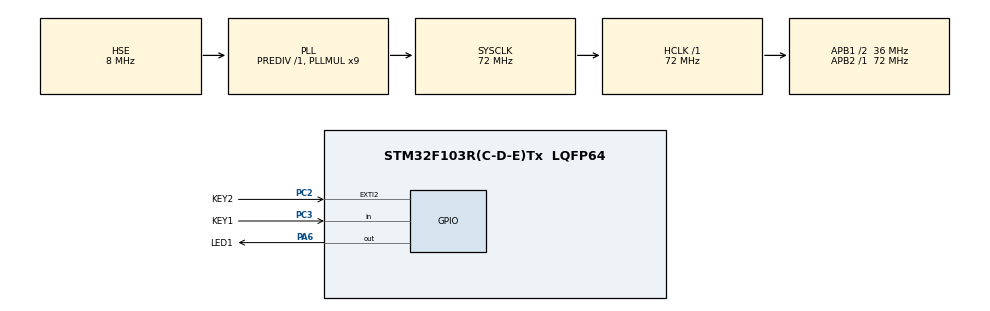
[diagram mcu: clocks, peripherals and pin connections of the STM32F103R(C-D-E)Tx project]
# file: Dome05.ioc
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Mcu.Family=STM32F1
Mcu.Name=STM32F103R(C-D-E)Tx
Mcu.Package=LQFP64
NVIC.EXTI2_IRQn=true\:2\:0\:true\:false\:true\:true\:true
NVIC.PriorityGroup=NVIC_PRIORITYGROUP_4
PA13.Mode=Serial_Wire
PA13.Signal=SYS_JTMS-SWDIO
PA14.Mode=Serial_Wire
PA14.Signal=SYS_JTCK-SWCLK
PA6.GPIO_Label=LED1
PA6.GPIO_PuPd=GPIO_PULLUP
PA6.PinState=GPIO_PIN_SET
PA6.Signal=GPIO_Output
PC2.GPIO_Label=KEY2
PC2.GPIO_ModeDefaultEXTI=GPIO_MODE_IT_RISING_FALLING
PC2.Signal=GPXTI2
PC3.GPIO_Label=KEY1
PC3.GPIO_PuPd=GPIO_NOPULL
PC3.Signal=GPIO_Input
PD0-OSC_IN.Mode=HSE-External-Oscillator
PD0-OSC_IN.Signal=RCC_OSC_IN
PD1-OSC_OUT.Mode=HSE-External-Oscillator
PD1-OSC_OUT.Signal=RCC_OSC_OUT
ProjectManager.HeapSize=0x200
ProjectManager.StackSize=0x400
ProjectManager.TargetToolchain=MDK-ARM V5.32
RCC.AHBFreq_Value=72000000
RCC.APB1CLKDivider=RCC_HCLK_DIV2
RCC.APB1Freq_Value=36000000
RCC.APB1TimFreq_Value=72000000
RCC.APB2Freq_Value=72000000
RCC.APB2TimFreq_Value=72000000
RCC.HCLKFreq_Value=72000000
RCC.PLLMUL=RCC_PLL_MUL9
RCC.PLLSourceVirtual=RCC_PLLSOURCE_HSE
RCC.SYSCLKFreq_VALUE=72000000
RCC.SYSCLKSource=RCC_SYSCLKSOURCE_PLLCLK
RCC.USBFreq_Value=72000000
board=custom

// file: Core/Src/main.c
/* USER CODE BEGIN Header */
/**
  ******************************************************************************
  * @file           : main.c
  * @brief          : Main program body
  ******************************************************************************
  * @attention
  *
  * Copyright (c) 2025 STMicroelectronics.
  * All rights reserved.
  *
  * This software is licensed under terms that can be found in the LICENSE file
  * in the root directory of this software component.
  * If no LICENSE file comes with this software, it is provided AS-IS.
  *
  ******************************************************************************
  */
/* USER CODE END Header */
#include "main.h"
#include "gpio.h"

void SystemClock_Config(void);

int main(void)
{

  /* MCU Configuration--------------------------------------------------------*/

  /* Reset of all peripherals, Initializes the Flash interface and the Systick. */
  HAL_Init();

  /* Configure the system clock */
  SystemClock_Config();

  /* Initialize all configured peripherals */
  MX_GPIO_Init();

  /* Infinite loop */
  /* USER CODE BEGIN WHILE */
  while (1)
  {
		HAL_Delay(5000);
		if(HAL_GPIO_ReadPin(KEY1_GPIO_Port, KEY1_Pin) == GPIO_PIN_RESET) {
			HAL_Delay(10);
			 if(HAL_GPIO_ReadPin(KEY1_GPIO_Port, KEY1_Pin) == GPIO_PIN_RESET) {
				 HAL_GPIO_TogglePin(LED1_GPIO_Port,LED1_Pin);
				 //HAL_Delay(3000);
				 while(HAL_GPIO_ReadPin(KEY1_GPIO_Port, KEY1_Pin) == GPIO_PIN_RESET);
			 }
		 }
    /* USER CODE END WHILE */

  }
}

void SystemClock_Config(void)
{
  RCC_OscInitTypeDef RCC_OscInitStruct = {0};
  RCC_ClkInitTypeDef RCC_ClkInitStruct = {0};

  /** Initializes the RCC Oscillators according to the specified parameters
  * in the RCC_OscInitTypeDef structure.
  */
  RCC_OscInitStruct.OscillatorType = RCC_OSCILLATORTYPE_HSE;
  RCC_OscInitStruct.HSEState = RCC_HSE_ON;
  RCC_OscInitStruct.HSEPredivValue = RCC_HSE_PREDIV_DIV1;
  RCC_OscInitStruct.HSIState = RCC_HSI_ON;
  RCC_OscInitStruct.PLL.PLLState = RCC_PLL_ON;
  RCC_OscInitStruct.PLL.PLLSource = RCC_PLLSOURCE_HSE;
  RCC_OscInitStruct.PLL.PLLMUL = RCC_PLL_MUL9;
  if (HAL_RCC_OscConfig(&RCC_OscInitStruct) != HAL_OK)
  {
    Error_Handler();
  }
  /** Initializes the CPU, AHB and APB buses clocks
  */
  RCC_ClkInitStruct.ClockType = RCC_CLOCKTYPE_HCLK|RCC_CLOCKTYPE_SYSCLK
                              |RCC_CLOCKTYPE_PCLK1|RCC_CLOCKTYPE_PCLK2;
  RCC_ClkInitStruct.SYSCLKSource = RCC_SYSCLKSOURCE_PLLCLK;
  RCC_ClkInitStruct.AHBCLKDivider = RCC_SYSCLK_DIV1;
  RCC_ClkInitStruct.APB1CLKDivider = RCC_HCLK_DIV2;
  RCC_ClkInitStruct.APB2CLKDivider = RCC_HCLK_DIV1;

  if (HAL_RCC_ClockConfig(&RCC_ClkInitStruct, FLASH_LATENCY_2) != HAL_OK)
  {
    Error_Handler();
  }
}

/* USER CODE BEGIN 4 */
uint32_t falling_tick = 0;
uint32_t rising_tick = 0;
 void HAL_GPIO_EXTI_Callback(uint16_t GPIO_Pin){
//	 if(GPIO_Pin == KEY2_Pin) {
//		HAL_Delay(10);
//		if(HAL_GPIO_ReadPin(KEY2_GPIO_Port,KEY2_Pin) == 0){
//			HAL_GPIO_TogglePin(LED1_GPIO_Port,LED1_Pin);
//		}
//
	 //中断中不应该有耗时的Delay，以下是优化
	 if(GPIO_Pin == KEY2_Pin){
		 if(HAL_GPIO_ReadPin(KEY2_GPIO_Port,KEY2_Pin) == 0){
			//下降沿触发
		 falling_tick = HAL_GetTick();
		}else if (HAL_GPIO_ReadPin(KEY2_GPIO_Port,KEY2_Pin) == 1 && falling_tick != 0){
			 //上升沿触发
			 rising_tick = HAL_GetTick();
			 if(rising_tick - falling_tick > 50) {
				HAL_GPIO_TogglePin(LED1_GPIO_Port,LED1_Pin);
		 }
			rising_tick = falling_tick = 0;
		}
	}
}
/* USER CODE END 4 */

void Error_Handler(void)
{
  __disable_irq();
  while (1)
  {
  }
}
